# ABE_CM_CORE_AON register map
Vendor: Texas Instruments
Peripheral module from a debugger description file (folder omap5430_ES2_PUBLIC).
Registers are 32-bit, access per field, reset 0x30000 unless marked. A register's access mark holds for its fields unless they carry their own. Offsets are as the file gives them; lines under a group give offsets from that group; [hi:lo] are bit positions; {n}, {i} and the like mark numbered series; 'fields as' and 'values as' point back to an identical list; <NAME> marks a mode.

## ABE_CM_CORE_AON
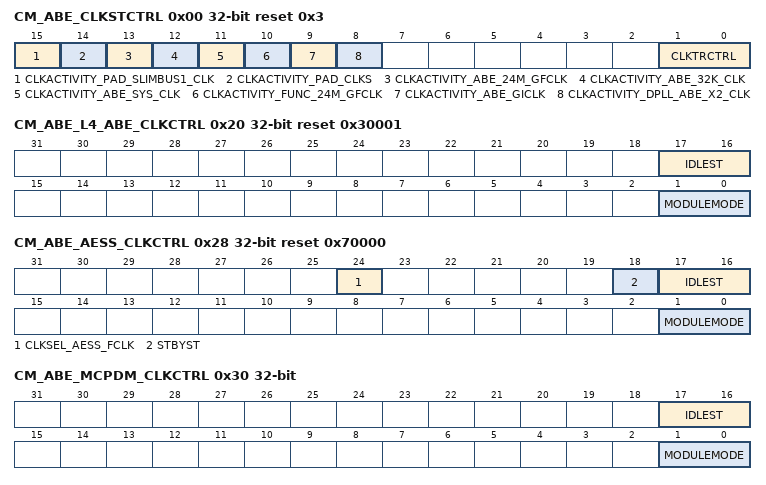
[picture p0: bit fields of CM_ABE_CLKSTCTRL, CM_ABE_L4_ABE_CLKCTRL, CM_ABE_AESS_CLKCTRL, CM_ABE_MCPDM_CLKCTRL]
0x00 CM_ABE_CLKSTCTRL reset 0x3 — This register enables the ABE domain power state transition. It controls the HW supervised domain power state transition between ON-ACTIVE and ON-INACTIVE states. It also holds 1 status bit per clock input of the domain.
  [15] CLKACTIVITY_PAD_SLIMBUS1_CLK ro — This field indicates the state of the SLIMBUS_CLK clock in the domain. [warm reset insensitive]
    0=Inact (Corresponding clock is definitely gated); 1=Act (Corresponding clock is running or gating/ungating transition is on-going)
  [14] CLKACTIVITY_PAD_CLKS ro — This field indicates the state of the PAD_CLKS clock in the domain. [warm reset insensitive]
    values as CLKACTIVITY_PAD_SLIMBUS1_CLK
  [13] CLKACTIVITY_ABE_24M_GFCLK ro — This field indicates the state of the ABE_24M_GFCLK clock in the domain. [warm reset insensitive]
    values as CLKACTIVITY_PAD_SLIMBUS1_CLK
  [12] CLKACTIVITY_ABE_32K_CLK ro — This field indicates the state of the ABE_32K_CLK clock in the domain. [warm reset insensitive]
    values as CLKACTIVITY_PAD_SLIMBUS1_CLK
  [11] CLKACTIVITY_ABE_SYS_CLK ro — This field indicates the state of the ABE_SYS_CLK clock in the domain. [warm reset insensitive]
    values as CLKACTIVITY_PAD_SLIMBUS1_CLK
  [10] CLKACTIVITY_FUNC_24M_GFCLK ro — This field indicates the state of the FUNC_24M_GFCLK clock in the domain. [warm reset insensitive]
    values as CLKACTIVITY_PAD_SLIMBUS1_CLK
  [9] CLKACTIVITY_ABE_GICLK ro — This field indicates the state of the ABE_GICLK interface clock in the domain. [warm reset insensitive]
    values as CLKACTIVITY_PAD_SLIMBUS1_CLK
  [8] CLKACTIVITY_DPLL_ABE_X2_CLK ro — This field indicates the state of the DPLL_ABE_X2_CLK clock in the domain. [warm reset insensitive]
    0=Corresponding_clock_is_definitely_gated; 1=CLKACTIVITY_DPLL_ABE_X2_CLK_1_r (Corresponding clock is running or gating/ungating transition is on-going)
  [1:0] CLKTRCTRL rw — Controls the clock state transition of the ABE clock domain.
    0=NO_SLEEP (NO_SLEEP: Sleep transition cannot be initiated. Wakeup transition may however occur.); 1=SW_SLEEP (SW_SLEEP: Start a software forced sleep transition on the domain.); 2=SW_WKUP (SW_WKUP: Start a software forced wake-up transition on the domain.); 3=HW_AUTO (HW_AUTO: Automatic transition is enabled. Sleep and wakeup transition are based upon hardware conditions.)
0x20 CM_ABE_L4_ABE_CLKCTRL ro reset 0x30001 — This register manages the L4ABE clocks.
  [17:16] IDLEST — Module idle status. [warm reset insensitive]
    0=Func (Module is fully functional, including INTRCONN); 1=Trans (Module is performing transition: wakeup, or sleep, or sleep abortion); 2=Idle (Module is in Idle mode (only INTRCONN part). It is functional if using separate functional clock); 3=Disable (Module is disabled and cannot be accessed)
  [1:0] MODULEMODE — Control the way mandatory clocks are managed.
    1=AUTO (Module is managed automatically by HW according to clock domain transition. A clock domain sleep transition put module into idle. A wakeup domain transition put it back into function. If[1:0] CLKTRCTRL = 0x3 (HW_AUTO), any INTRCONN access to module is always granted. Module clocks may be gated according to the clock domain state.)
0x28 CM_ABE_AESS_CLKCTRL reset 0x70000 — This register manages the AESS clocks.
  [24] CLKSEL_AESS_FCLK rw — Selects the ratio of AESS_FCLK to ABE_CLK
    0=DIV1 (AESS_FCLK is divide by 1 of ABE_CLK); 1=DIV2 (AESS_FCLK is divide by 2 of ABE_CLK)
  [18] STBYST ro — Module standby status. [warm reset insensitive]
    0=Func (Module is functional (not in standby)); 1=Standby (Module is in standby)
  [17:16] IDLEST ro — Module idle status. [warm reset insensitive]
    values as CM_ABE_L4_ABE_CLKCTRL.IDLEST
  [1:0] MODULEMODE rw — Control the way mandatory clocks are managed.
    0=DISABLED (Module is disable by SW. Any INTRCONN access to module results in an error, except if resulting from a module wakeup (asynchronous wakeup).); 2=ENABLE (Module is explicitly enabled. Interface clock (if not used for functions) may be gated according to the clock domain state. Functional clocks are guarantied to stay present. As long as in this configuration, power domain sleep transition cannot happen.)
0x30 CM_ABE_MCPDM_CLKCTRL — This register manages the McPDM clocks.
  [17:16] IDLEST ro — Module idle status. [warm reset insensitive]
    values as CM_ABE_L4_ABE_CLKCTRL.IDLEST
  [1:0] MODULEMODE rw — Control the way mandatory clocks are managed.
    values as CM_ABE_AESS_CLKCTRL.MODULEMODE
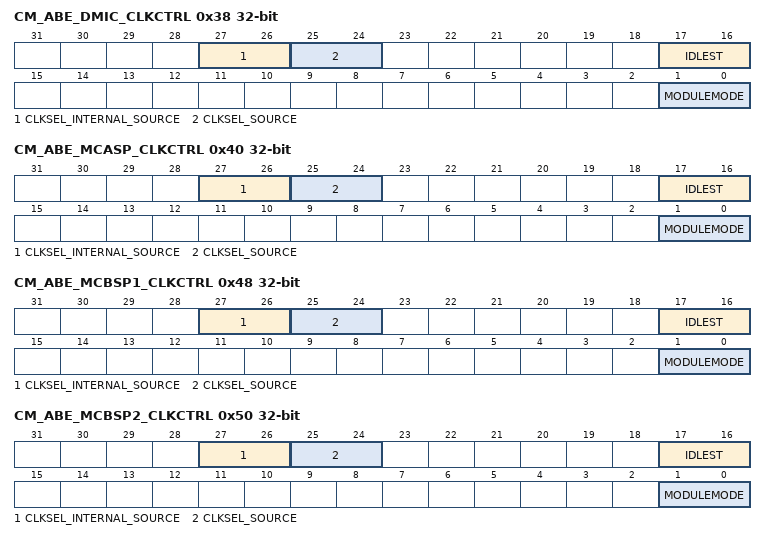
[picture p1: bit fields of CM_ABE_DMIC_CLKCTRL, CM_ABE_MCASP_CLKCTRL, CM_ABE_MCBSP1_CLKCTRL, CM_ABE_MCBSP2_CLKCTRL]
0x38 CM_ABE_DMIC_CLKCTRL — This register manages the DMIC clocks.
  [27:26] CLKSEL_INTERNAL_SOURCE rw — Selects the internal clock to be used as the functional clock in case CLKSEL_SOURCE selects the internal clock source as the functional clock source.
    0=SEL_ABE_24M (24MHz clock derived from DPLL_ABE is selected); 1=SEL_ABE_SYSCLK (ABE_SYS_CLK is selected); 2=SEL_PER_24M (24MHz clock derived from DPLL_PER is selected)
  [25:24] CLKSEL_SOURCE rw — Selects the source of the functional clock between, internal source, CLKS pad and Audio SLIMBUS_CLK pad. The switching between the clocks is not guaranteed to be glitchless.
    0=SEL_INTERNAL (Functional clock is sourced from an internal clock); 1=SEL_CLKS (Functional clock is sourced from CLKS pad); 2=SEL_SLIMBUS_CLK (Functional clock is sourced from Audio SLIMBUS pad)
  [17:16] IDLEST ro — Module idle status. [warm reset insensitive]
    values as CM_ABE_L4_ABE_CLKCTRL.IDLEST
  [1:0] MODULEMODE rw — Control the way mandatory clocks are managed.
    values as CM_ABE_AESS_CLKCTRL.MODULEMODE
0x40 CM_ABE_MCASP_CLKCTRL — This register manages the MCASP clocks.
  [27:26] CLKSEL_INTERNAL_SOURCE rw — Selects the internal clock to be used as the functional clock in case CLKSEL_SOURCE selects the internal clock source as the functional clock source.
    values as CM_ABE_DMIC_CLKCTRL.CLKSEL_INTERNAL_SOURCE
  [25:24] CLKSEL_SOURCE rw — Selects the source of the functional clock between, internal source, CLKS pad and Audio SLIMBUS_CLK pad. The switching between the clocks is not guaranteed to be glitchless.
    0=SEL_INTERNAL (Functional clock is sourced from an internal clock); 1=SEL_CLKS (Functional clock is sourced from CLKS pad); 2=SEL_SLIMBUS_CLK (Functional clock is sourced from Audio SIMBUS pad)
  [17:16] IDLEST ro — Module idle status. [warm reset insensitive]
    values as CM_ABE_L4_ABE_CLKCTRL.IDLEST
  [1:0] MODULEMODE rw — Control the way mandatory clocks are managed.
    values as CM_ABE_AESS_CLKCTRL.MODULEMODE
0x48 CM_ABE_MCBSP1_CLKCTRL — This register manages the MCBSP1 clocks.
  fields as CM_ABE_MCASP_CLKCTRL
0x50 CM_ABE_MCBSP2_CLKCTRL — This register manages the MCBSP2 clocks.
  fields as CM_ABE_MCASP_CLKCTRL
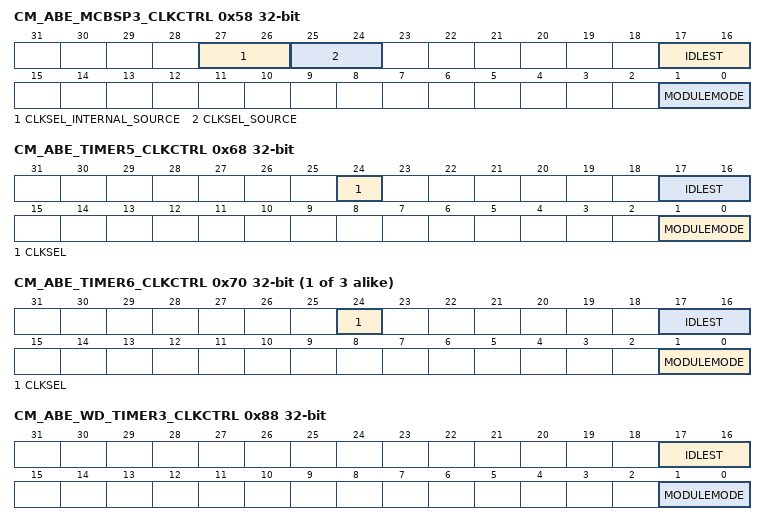
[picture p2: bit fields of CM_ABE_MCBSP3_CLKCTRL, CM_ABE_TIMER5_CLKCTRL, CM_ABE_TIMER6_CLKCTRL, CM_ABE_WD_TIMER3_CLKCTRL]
0x58 CM_ABE_MCBSP3_CLKCTRL — This register manages the MCBSP3 clocks.
  fields as CM_ABE_DMIC_CLKCTRL
0x68 CM_ABE_TIMER5_CLKCTRL — This register manages the TIMER5 clocks.
  [24] CLKSEL rw — Selects between ABE_SYS_CLK and ABE_32K_CLK as the timer functional clock
    0=SEL_ABE_SYSCLK (Selects ABE_SYS_CLK as the functional clock); 1=SEL_ABE_ALWON_32K_CLK (Selects ABE_32K_CLK as the functional clock)
  [17:16] IDLEST ro — Module idle status [warm reset insensitive]
    values as CM_ABE_L4_ABE_CLKCTRL.IDLEST
  [1:0] MODULEMODE rw — Control the way mandatory clocks are managed.
    values as CM_ABE_AESS_CLKCTRL.MODULEMODE
{0x40+8i} CM_ABE_TIMER{i}_CLKCTRL (i=6..8) — This register manages the TIMER{i} clocks.
  [24] CLKSEL rw — Selects between ABE_SYS_CLK and ABE_32K_CLK as the timer functional clock
    values as CM_ABE_TIMER5_CLKCTRL.CLKSEL
  [17:16] IDLEST ro — Module idle status. [warm reset insensitive]
    values as CM_ABE_L4_ABE_CLKCTRL.IDLEST
  [1:0] MODULEMODE rw — Control the way mandatory clocks are managed.
    values as CM_ABE_AESS_CLKCTRL.MODULEMODE
0x88 CM_ABE_WD_TIMER3_CLKCTRL — This register manages the WD_TIMER3 clocks.
  fields as CM_ABE_MCPDM_CLKCTRL
